# SLIMBUS2_L3Interconnect register map
Vendor: Texas Instruments
Registers are 32-bit, access per field, reset 0x0 unless marked. A register's access mark holds for its fields unless they carry their own. Offsets are as the file gives them; [hi:lo] are bit positions; {n}, {i} and the like mark numbered series; 'fields as' and 'values as' point back to an identical list; <NAME> marks a mode.

## SLIMBUS2_L3Interconnect (part 2 of 2)
0x78 SLIMBUS_FL_SM — Subframe mode (SM: defines control vs. data space partition) control and status Software must write in values : a) to use when booting in active framer mode. b) extracted from NEXT_SUBFRAME_MODE(SM), to use at following reconfiguration boundary. Hardware-updated upon superframe sync acquisition, when booting in clock receiver mode.
  [4:0] SM rw — Subframe Mode, which sets Control Space Width (CSW) and Subframe Length (SFL), both expressed in slots. Note that we always have CSW &lt;= SFL since the control is included in the subframe.
    13=CSW=3; SFL=8 (37.5% control); 21=CSW=6; SFL=8 (75% control); 30=reserved. Same effect than 0b00000; 8=CSW=2; SFL=6 (33.3% control); 5=CSW=1; SFL=8 (12.5% control); 27=CSW=12; SFL=32 (37.5% control); 2=reserved. Same as 0x00; 4=CSW=1; SFL=6 (16.7% control); 6=CSW=1; SFL=24 (4.17% control); 1=reserved. Same as 0x05; 29=CSW=16; SFL=32 (50% control); 0=CSW=8; SFL=8 (100% control vs. 0% data); 11=CSW=2; SFL=32 (6.25% control); 3=reserved. Same as 0x07; 23=CSW=6; SFL=32 (18.8% control); 17=CSW=4; SFL=8 (50% control); 10=CSW=2; SFL=24 (8.33% control); 9=CSW=2; SFL=8 (25% control); 16=CSW=4; SFL=6 (66.7% control); 18=CSW=4; SFL=24 (16.7% control); 19=CSW=4; SFL=32 (12.5% control); 24=CSW=8; SFL=24 (33.3% control); 20=reserved. Same as 0x00; 14=CSW=3; SFL=24 (12.5% control); 22=CSW=6; SFL=24 (25% control); 28=CSW=16; SFL=24 (66.7% control); 7=CSW=1; SFL=32 (3.13% control); 25=CSW=8; SFL=32 (25% control); 31=CSW=24; SFL=32 (75% control); 26=CSW=12; SFL=24 (50% control); 15=CSW=3; SFL=32 (9.38% control); 12=CSW=3; SFL=6 (50% control)
0x7C SLIMBUS_FL_CG — Clock Gear (CG) control and status Software must write in values : a) to use when booting in active framer mode. b) extracted from NEXT_CLOCK_GEAR(CG), to use at following reconfiguration boundary. Hardware-updated upon superframe sync acquisition, when booting in clock receiver mode.
  [3:0] CG rw — Clock Gear (CG) to be used after the next reconfiguration boundary. Root / SLIMbus frequency ratio is defined as 2
    6=Ratio to root frequency: 16; 1=Ratio to root frequency: 512; 10=Ratio to root frequency: 1 (undivided); 7=Ratio to root frequency: 8; 3=Ratio to root frequency: 128; 2=Ratio to root frequency: 256; 8=Ratio to root frequency: 4; 9=Ratio to root frequency: 2; 5=Ratio to root frequency: 32; 4=Ratio to root frequency: 64
0x80 SLIMBUS_FL_RF — Root frequency (RF = SLIMbus clock frequency when in gear 10) control and status Software must write in values : a) to use when booting in active framer mode. b) extracted from NEXT_ROOT_FREQUENCY(RF), to use at following reconfiguration boundary. Hardware-updated upon superframe sync acquisition, when booting in clock receiver mode.
  [3:0] RF rw — Root frequency
    {v}={v+18} MHz (v=6..9); 1=24.576 MHz; 0=Root frequency not indicated; 2=22.5792 MHz; 4=16.8 MHz; 5=19.2 MHz; 3=15.36 MHz
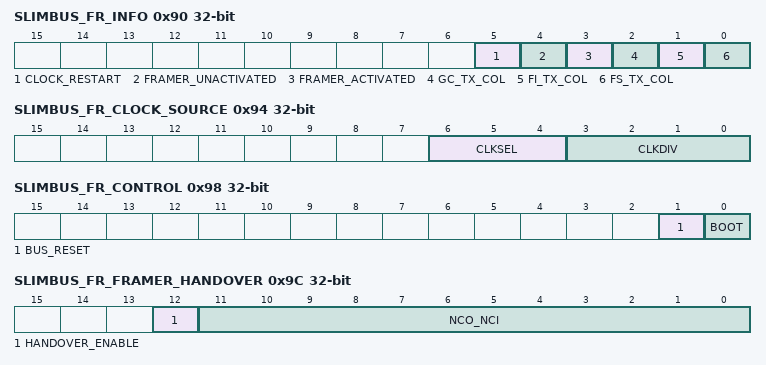
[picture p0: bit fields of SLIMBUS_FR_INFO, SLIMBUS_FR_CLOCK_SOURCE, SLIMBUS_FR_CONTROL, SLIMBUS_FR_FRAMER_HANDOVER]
0x90 SLIMBUS_FR_INFO access not given — Framer device status (when active). Write 1 to a bit to clear it.
  [all] fields
    0=no event pending; 1=event pending
  [5] CLOCK_RESTART — Clock restart request event detected (that is, asynchronous DATA line transition during clock pause) (access RW W1toClr)
  [4] FRAMER_UNACTIVATED — Framer has left clock source operational state. Set on ACTIVE_FRAMER information element deassertion. (framer device class-specific IE) (access RW W1toClr)
  [3] FRAMER_ACTIVATED — Framer has reached clock source operational state. Set on ACTIVE_FRAMER information element assertion. (framer device class-specific IE) (access RW W1toClr)
  [2] GC_TX_COL — Collision during guide byte transmit (Guide Channel) Framer device class-specific information element (IE) (access RW W1toClr)
  [1] FI_TX_COL — Collision during Framing Information transmit (framing channel) Framer device class-specific information element (IE) (access RW W1toClr)
  [0] FS_TX_COL — Collision during Frame Sync symbol transmit (framing channel) Framer device class-specific information element (IE) (access RW W1toClr)
0x94 SLIMBUS_FR_CLOCK_SOURCE — Root clock configuration for active framer mode, used at next reconfiguration boundary. Unused when not active framer.
  [6:4] CLKSEL rw — SLIMbus clock selection
    0=FCLK1; 1=FCLK2; 2=FCLK3
  [3:0] CLKDIV rw — Root divider ratio, applied on clock input to obtain root clock, to be used at next reconfiguration boundary. Input/ root frequency ratio is defined as 2 With CG the SLIMbus clock gear, Input / SLIMbus frequency ratio is therefore 2 WARNING: that last ratio has to be 1 or greater, to be implementable by the actual clock divider.
    6=Ratio is 2; 1=Ratio is 1/16: Gears 7 to 10 forbidden; 10=Ratio is 32; 7=Ratio is 4; 0=Ratio is 1/32: Gears 6 to 10 forbidden; 2=Ratio is 1/8: Gears 8 to 10 forbidden; 8=Ratio is 8; 9=Ratio is 16; 4=Ratio is 1/2: Gear 10 forbidden; 5=Ratio is 1 (root freq. = input freq.); 3=Ratio is 1/4: Gears 9-10 forbidden
0x98 SLIMBUS_FR_CONTROL — Framer Device control. Unused when not active framer. (Self-cleared bits)
  [1] BUS_RESET rw — Bus reset request control, when framer is already active. Set upon reception of the NEXT_RESET_BUS() message. Transitions clock source FSM to state 'StartingClock' (from 'Operational').
    0=BUS_RESET_0_w (Cancel pending request (not used in normal operation) if any, otherwise no action); 1=BUS_RESET_1_w (Assert request for next reconfiguration); 1=BUS_RESET_1_r (Request pending for next reconfiguration); 0=BUS_RESET_0_r (No request pending for next reconfiguration)
  [0] BOOT rw — Initiate an active framer (clock source) boot sequence for the component, that is, when component is default active framer. Transitions clock source FSM from state 'Undefined' to 'CheckingDataLine'. Transitions clock receiver FSM from state 'Undefined' to 'Reset'. No effect if bus has already booted.
    0=BOOT_0_w (Cancel pending request (not used in normal operation) if any, otherwise no action); 1=BOOT_1_w (Assert request for next reconfiguration); 1=BOOT_1_r (Request pending for next reconfiguration); 0=BOOT_0_r (No request pending for next reconfiguration)
0x9C SLIMBUS_FR_FRAMER_HANDOVER — Framer handover control (outgoing if currently active, incoming if currently inactive)
  [12] HANDOVER_ENABLE rw — Enable framer handover, upon NEXT_ACTIVE_FRAMER(NCi,NCo) reception. Self-cleared upon handover, that is, at next reconfiguration boundary.
    0=No framer handover; 1=Framer handover at next configuration boundary
  [11:0] NCO_NCI rw — NCo[11:0] / NCi[11:0] for outgoing / incoming framer respectively, as extracted from NEXT_ACTIVE_FRAMER(NCi,NCo) Used on framer handover at next reconfiguration boundary.
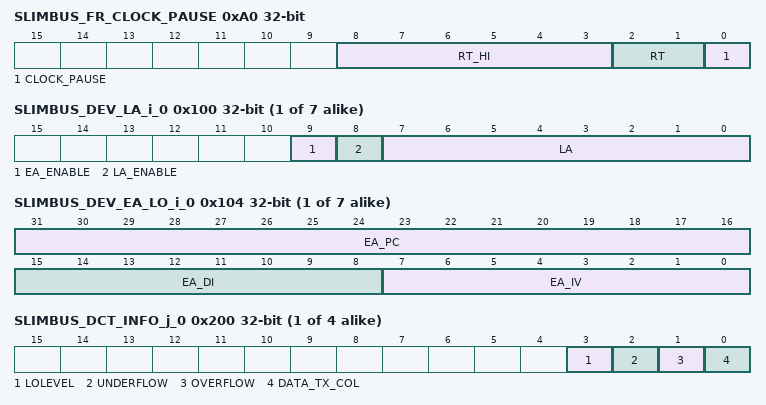
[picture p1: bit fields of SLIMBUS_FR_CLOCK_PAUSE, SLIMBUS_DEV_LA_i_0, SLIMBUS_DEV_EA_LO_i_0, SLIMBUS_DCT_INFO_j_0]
0xA0 SLIMBUS_FR_CLOCK_PAUSE — Clock and pause restart control. Applied at following reconfiguration boundary, that is, where the clock is paused. Note that programming is indentical for an active framer (clock source) and a clock receiver.
  [8:3] RT_HI ro — MSBs of 8-bit SLIMbus parameter. Constant.
    0=RT_HI_0_r (Only legal, unreserved value.)
  [2:1] RT rw — Restart Time (RT) for recovery after clock pause, as extracted from NEXT_PAUSE_CLOCK(RT) LSBs of 8-bit SLIMbus parameter. Unused when not active framer.
    0=Fast recovery (less than 4 cells); 1=Constant-phase recovery (superframe phase preserved); 2=Unspecified recovery delay
  [0] CLOCK_PAUSE rw — Control clock pause / restart. Self-cleared upon restart.
    0=Force clock restart if paused, no effect otherwise; 1=Pause clock (clock source) or expect clock pause (clock receiver) at next configuration boundary
{0x100+0x10*i} SLIMBUS_DEV_LA_i_{i} (i=0..6) — Device Logical Address control
  [9] EA_ENABLE rw — Enables the reception of 'long-header' messages to the device's hardwired Enumeration Address (EA). Don't care if LA_ENABLE is 1.
    0=EA is not valid; 1=EA is used for message reception
  [8] LA_ENABLE rw — Enables the reception of 'short-header' messages to the device's Logical Address (LA).
    0=LA is not valid; 1=LA valid, to be used for message reception
  [7:0] LA rw — Device Logical Address, assigned by manager device at enumeration (0x00 through 0xEF). The active manager device itself has address 0xFF by default.
    255=active manager device address
{0x104+0x10*i} SLIMBUS_DEV_EA_LO_i_{i} ro (i=0..6) — Device's Enumeration Address (EA[47:0]), lower 32 bits. For reference.
  [31:16] EA_PC — Product Code (PC[15:0]), shared by all devices of the component
  [15:8] EA_DI — Device Index (DI[15:0]), hardcoded from 0 upwards (0x00,0x01,0x02, etc...) each device of the component. WARNING: value is incorrectly given as 0x00 for all indexes.
  [7:0] EA_IV — Component's Instance Value (IV[7:0]), shared by all devices of the component
{0x108+0x10*i} SLIMBUS_DEV_EA_HI_i_{i} ro reset 0x102 (i=0..6) — Device's Enumeration Address (EA[47:0]), upper 16 bits. For reference.
  [15:0] EA_MI — Manufacturer Index (MI[15:0]), shared by all devices
{0x200+0x20*i} SLIMBUS_DCT_INFO_j_{i} access not given (i=0..3) — TX data agent status. Write 1 to a bit to clear it.
  [3] LOLEVEL — Write level of TX data agent FIFO has gone above DMA threshold (that is, writes required to fill FIFO) Note: Defaults to 0 (even though FIFO is then empty) as it sets to 1 only when read-only status bit DCT_FIFO_STATUS.LOLEVEL transitions from 0 to 1, that is, when threshold is actually crossed downward. (access RW W1toClr)
    0=LOLEVEL_0_w (No action); 1=LOLEVEL_1_w (Clear pending event, if any); 1=LOLEVEL_1_r (IRQ event pending); 0=LOLEVEL_0_r (No event pending)
  [2] UNDERFLOW — Underflow in TX data agent FIFO. Note: never asserted in pushed or async TPs, by construction. (access RW W1toClr)
    0=UNDERFLOW_0_w (No action); 1=UNDERFLOW_1_w (Clear pending event, if any); 1=UNDERFLOW_1_r (IRQ event pending); 0=UNDERFLOW_0_r (No event pending)
  [1] OVERFLOW — Overflow in TX data agent FIFO. (access RW W1toClr)
    0=OVERFLOW_0_w (No action); 1=OVERFLOW_1_w (Clear pending event, if any); 1=OVERFLOW_1_r (IRQ event pending); 0=OVERFLOW_0_r (No event pending)
  [0] DATA_TX_COL — TX collision in TX data agent. Core information element (IE). (access RW W1toClr)
    0=DATA_TX_COL_0_w (No action); 1=DATA_TX_COL_1_w (Clear pending event, if any); 1=DATA_TX_COL_1_r (IRQ event pending); 0=DATA_TX_COL_0_r (No event pending)
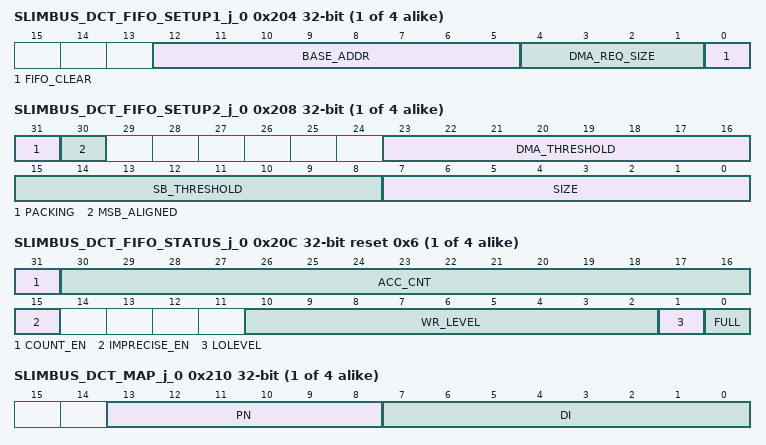
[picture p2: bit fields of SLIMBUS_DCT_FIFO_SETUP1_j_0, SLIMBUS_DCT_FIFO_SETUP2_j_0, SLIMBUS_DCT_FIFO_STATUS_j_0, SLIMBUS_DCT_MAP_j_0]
{0x204+0x20*i} SLIMBUS_DCT_FIFO_SETUP1_j_{i} (i=0..3) — TX data agent FIFO setup. To be kept static during channel operation.
  [12:5] BASE_ADDR rw — TX data agent FIFO base address within shared TX RAM. (physical address of the 32-bit wide RAM array)
  [4:1] DMA_REQ_SIZE rw — DMA request size minus 1, in write accesses. In counting (packet) mode, last request may be smaller. Only applicable in precise DMA mode.
    15=16 accesses per DMA request; 0=1 access per DMA request
  [0] FIFO_CLEAR rw — Returns FIFO to initial empty state.
    0=FIFO_CLEAR_0_w (No effect); 1=FIFO_CLEAR_1_w (Clear FIFO); 1=FIFO_CLEAR_1_r (Ongoing Clear. Completion requires the SLIMbus clock.); 0=FIFO_CLEAR_0_r (No event, last clear completed)
{0x208+0x20*i} SLIMBUS_DCT_FIFO_SETUP2_j_{i} (i=0..3) — TX data agent FIFO setup, continued. To be kept static during channel operation.
  [31] PACKING rw — Packing enable control
    0=Packing disabled: one segment word per write access. Byte enable is don't care.; 1=Packing enabled: one or several segment words per write access, depending on segment word size and byte enable. Only works in LSB-aligned mode. Behaviour in LSB-aligned mode is undefined.
  [30] MSB_ALIGNED rw — PLACEHOLDER, NO EFFECT: DATA ALWAYS LSB-aligned LSB/MSB-alignment of FIFO input (write) TX data.
    0=Input data is LSB-aligned; 1=Input data is MSB-aligned
  [23:16] DMA_THRESHOLD rw — SW-side TX data agent FIFO threshold. DMA write requests get (re-)asserted when WR_LEVEL is above threshold. Range: 0 to SIZE field value (included).
    255=DMA writes requested whenever FIFO is empty (assuming maximum FIFO size); 0=DMA writes requested whenever FIFO is not full
  [15:8] SB_THRESHOLD rw — SLIMbus-side TX data agent FIFO threshold, used for SLIMbus transmission.
    255=Threshold condition = FIFO is full (assuming maximum FIFO size); 0=Threshold condition = FIFO is not empty
  [7:0] SIZE rw — Capacity of FIFO in segment words, minus one.
    255=Maximum FIFO size; 0=FIFO is 1-word deep (not recommended); 3=FIFO is 4-word deep. Recommended minimum setting (SLIMbus protocol).
{0x20C+0x20*i} SLIMBUS_DCT_FIFO_STATUS_j_{i} reset 0x6 (i=0..3) — TX data agent FIFO status, for software (non-DMA) FIFO management.
  [31] COUNT_EN rw — Down-counter mode control. Only applicable in precise DMA mode.
    0=COUNT_EN_0_w (Disable down-counter mode. Should typically be used only when ACC_CNT = 0. If ACC_CNT > 0, DMA request gets deasserted immediately.); 1=COUNT_EN_1_w (Enable down-counter mode. ACC_CNT is typically set to the desired value in the same write access.); 1=COUNT_EN_1_r (Down-counter mode is enabled. DMA request can only be active when ACC_CNT > 0); 0=COUNT_EN_0_r (Down-counter mode is disabled: DMA request follows FIFO level, and is active during no-tx periods.)
  [30:16] ACC_CNT rw — 'Packet mode' down-counter of segment words, decremented on DCT_DATA write accesses. In that mode, DMA request shall deassert when ACC_CNT = 0 (that is, packet fully transmitted / stored in TX FIFO).
    0=ACC_CNT_0_w (Deasserts current DMA request by forcing the count to zero (not typical operation)); 127=ACC_CNT_127_w (Set largest packet size (in accesses) to transfer before DMA request deassertion. Any lower value is also valid to enter.); 127=ACC_CNT_127_r (Maximum number of accesses still to be transferred before DMA deassertion. Unless interrupted, counter shall go through all values down to zero.); 0=ACC_CNT_0_r (No access left to transfer, DMA request currently inactive.)
  [15] IMPRECISE_EN rw — Precise vs. Imprecise DMA requesting mode control. (A DMA request is a single assertion-deassertion cycle.)
    0=DMA request contains a precise number of accesses; 1=DMA request is not expected to trigger a fixed number of accesses
  [10:2] WR_LEVEL ro — Number of free segment words in FIFO, that could be filled by writes.
    0x100=WR_LEVEL_256_r (FIFO is empty and entirely available for writes (assuming maximum FIFO size)); 0=WR_LEVEL_0_r (FIFO is full and cannot be written to)
  [1] LOLEVEL ro — Indicator of write level (WR_LEVEL: number of free words in FIFO) with respect to (write) threshold (DMA_threshold). Activates DMA write requests when high.
    1=LOLEVEL_1_r (WR_LEVEL > DMA_THRESHOLD); 0=LOLEVEL_0_r (WR_LEVEL <= DMA_THRESHOLD)
  [0] FULL ro — FIFO full indicator
    1=FULL_1_r (no space left in FIFO to write a word (WR_LEVEL = 0)); 0=FULL_0_r (some space left in FIFO to write at least one word (WR_LEVEL > 0))
{0x210+0x20*i} SLIMBUS_DCT_MAP_j_{i} (i=0..3) — Associates a device and port to the TX data agent. Write to field FL_CONTROL.validate_dcmap to validate changes.
  [13:8] PN rw — Port Number (PN), identifies the data channel's port for the device. Shall be unique within a device. Note that a half-duplex (bidirectional) port has 2 data agents with the same PN, 1 TX + 1 Rx.
  [7:0] DI rw — Index (DI) of the device this data agent belongs to. Devices are hard-indexed from 0 upwards.
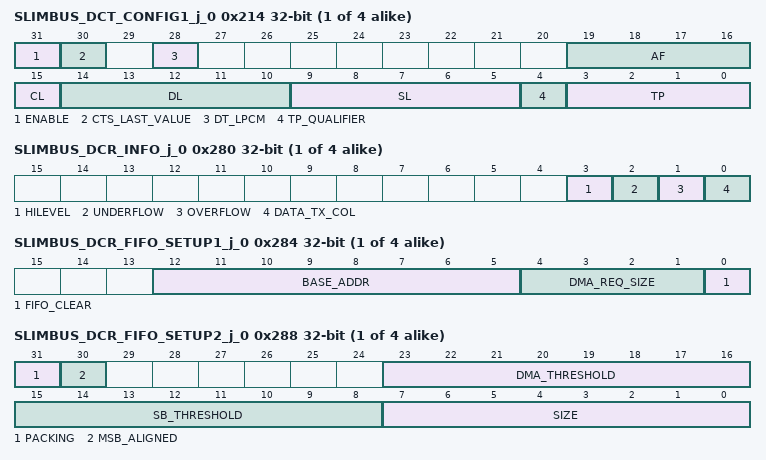
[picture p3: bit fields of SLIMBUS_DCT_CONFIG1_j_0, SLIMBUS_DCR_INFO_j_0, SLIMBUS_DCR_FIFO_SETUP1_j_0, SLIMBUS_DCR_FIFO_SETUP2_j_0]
{0x214+0x20*i} SLIMBUS_DCT_CONFIG1_j_{i} (i=0..3) — TX data agent configuration, applied at the next reconfiguration boundary
  [31] ENABLE rw — Data agent enabling control. Auto-cleared upon frame or superframe sync loss.
    1=ENABLE_1_r (Data agent is enabled); 0=ENABLE_0_r (Data agent is disabled)
  [30] CTS_LAST_VALUE ro — Last received value of the CTS TAG bit. Only updated for asynchronous TP, when primary owner (that is, transmitter) of the channel.
    1=CTS_LAST_VALUE_1_r (Local sink signals TAG.CTS=1 that is, it can receive data (and remote source can transmit some)); 0=CTS_LAST_VALUE_0_r (Local sink signals TAG.CTS=0 that is, it cannot receive any data (and remote source shall not transmit any))
  [28] DT_LPCM rw — Unsigned-to-OSAM encoding enable for Data Type (DT) = LPCM audio (0x1)
    0=DT!=0x1: encoding disabled; 1=DT=0x1: encoding enabled
  [19:16] AF rw — Auxillairy Format (AF) used in segment word size calculation. Non-zero values not supported in extended asynchronous TPs.
    15=User-defined 8-bit AUX (2 AUX slot per segment); 0=No AUX information (0 AUX slots per segment); 1=ZCUV for tunneling IEC60958 (1 AUX slot per segment); 11=User-defined 4-bit AUX (1 AUX slot per segment)
  [15] CL rw — Channel Link (CL) enable: Pairing up of current channel with previous one (that is, channel index below) Tied-0, read-only field for channel index 0, since there is no 'previous' channel in that case. TP and segment interval (encoded in SD) must be equal between the linked channels.
    0=Current channel independent from previous one; 1=Current channel paired up with previous one
  [14:10] DL rw — Segment Data Length (DL), in 4-bit slots (except when 0). AUX + DATA length shall fit in a segment word, that is, 1 to 32 bits. In extended async TPs, sets segment word size (0 and odd values illegal) instead.
    6=6 slots (24 bits); 1=1 slot (4 bits); 7=7 slots (28 bits), requiring at most 1 AUX slot to fit in max-size 32-bit segment word; 0=Length not indicated: Segment slots that are not TAG or AUX are DATA (that is, no unused slot); 2=2 slots (8 bits); 8=8 slots (32 bits), requiring zero AUX slot, to fit in a max-size 32-bit segment word; 4=4 slots (16 bits); 5=5 slots (20 bits); 3=3 slots (12 bits)
  [9:5] SL rw — total Segment Length (SL), in 4-bit slots. SL &gt;= TAG length + AUX length + DATA length
    0=Reseved value
  [4] TP_QUALIFIER rw — Qualifier for plain/extended half-duplex asynchronous TPs (owner ID). Unused and don't care for other TPs.
    0=1/2 duplex TPs: Local device is primary channel owner, uses T1 token; 1=1/2 duplex TPs: Local device is secondary channel owner, uses T2 token
  [3:0] TP rw — Transport Protocol (TP) Determines also the TAG length (from 0 to 2 slots).
    6=Extended asynchronous-half-duplex (unicast, 2-slot TAG); 1=Pushed (multicast, 1-slot TAG); 7=Extended asynchronous-simplex (unicast, 2-slot TAG); 0=Isochronous (multicast, no TAG); 2=Pulled (unicast, 1-slot TAG); 4=Asynchronous-simplex (unicast, 1-slot TAG); 5=Asynchronous-half-duplex (unicast, 1-slot TAG); 15=User-defined protocol 2 NOT SUPPORTED, RESERVED VALUE; 3=Locked (multicast, no TAG) NOT SUPPORTED, RESERVED VALUE; 14=User-defined protocol 1 NOT SUPPORTED, RESERVED VALUE
{0x218+0x20*i} SLIMBUS_DCT_CONFIG2_j_{i} (i=0..3) — TX data agent configuration (continued), applied at the next reconfiguration boundary
  [11:0] SD rw — Segment Distribution (see)
{0x21C+0x20*i} SLIMBUS_DCT_DATA_j_{i} rw (i=0..3) — TX data agent DATA FIFO input. Reads have no effect on FIFO.
  [31:0] DATA — Data segment word, single-word or packed, LSB or MSB-aligned.
{0x280+0x20*i} SLIMBUS_DCR_INFO_j_{i} access not given (i=0..3) — RX data agent status. Write 1 to a bit to clear it.
  [3] HILEVEL — Read level of RX data agent FIFO has gone above DMA threshold (that is, reads required to empty FIFO) (access RW W1toClr)
    0=HILEVEL_0_w (No action); 1=HILEVEL_1_w (Clear pending event, if any); 1=HILEVEL_1_r (IRQ event pending); 0=HILEVEL_0_r (No event pending)
  [2] UNDERFLOW — Underflow in RX data agent FIFO (access RW W1toClr)
    values as SLIMBUS_DCT_INFO_j_0.UNDERFLOW
  [1] OVERFLOW — Overflow in RX data agent FIFO Note: never asserted in pulled or async TPs, by construction. (access RW W1toClr)
    values as SLIMBUS_DCT_INFO_j_0.OVERFLOW
  [0] DATA_TX_COL — TX collision in RX data agent. Core information element (IE). (access RW W1toClr)
    values as SLIMBUS_DCT_INFO_j_0.DATA_TX_COL
{0x284+0x20*i} SLIMBUS_DCR_FIFO_SETUP1_j_{i} (i=0..3) — RX data agent FIFO setup. To be kept static during channel operation.
  [12:5] BASE_ADDR rw — RX data agent FIFO base address within shared RX RAM. (physical address of the 32-bit wide RAM array)
  [4:1] DMA_REQ_SIZE rw — DMA request size minus 1, in read accesses. In counting (packet) mode, last request may be smaller. Only applicable in precise DMA mode.
    15=16 accesses per DMA request; 0=1 access per DMA request
  [0] FIFO_CLEAR rw — Returns FIFO to initial empty state.
    values as SLIMBUS_DCT_FIFO_SETUP1_j_0.FIFO_CLEAR
{0x288+0x20*i} SLIMBUS_DCR_FIFO_SETUP2_j_{i} (i=0..3) — RX data agent FIFO setup, continued. To be kept static during channel operation.
  [31] PACKING rw — Packing enable control
    0=Packing disabled: one segment word per read access. Byte enable is don't care.; 1=Packing enabled: one or several segment words per read access, depending on segment word size and byte enable. Only works in LSB-aligned mode. Behaviour in LSB-aligned mode is undefined.
  [30] MSB_ALIGNED rw — PLACEHOLDER, NO EFFECT: DATA ALWAYS LSB-aligned LSB/MSB-alignment of FIFO output (read) RX data.
    0=Output data is LSB-aligned; 1=Output data is MSB-aligned
  [23:16] DMA_THRESHOLD rw — SW-side RX data agent FIFO threshold. DMA read requests get (re-)asserted when RD_LEVEL is above threshold. Range: 0 to SIZE field value (included).
    255=DMA reads requested whenever FIFO is full (assuming maximum FIFO size); 0=DMA reads requested whenever FIFO is not empty
  [15:8] SB_THRESHOLD rw — SLIMbus-side RX data agent FIFO threshold, used for SLIMbus reception.
    values as SLIMBUS_DCT_FIFO_SETUP2_j_0.SB_THRESHOLD
  [7:0] SIZE rw — Capacity of FIFO in segment words, minus one.
    values as SLIMBUS_DCT_FIFO_SETUP2_j_0.SIZE
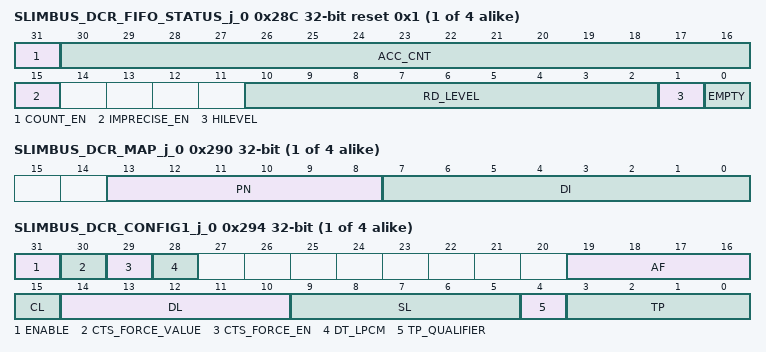
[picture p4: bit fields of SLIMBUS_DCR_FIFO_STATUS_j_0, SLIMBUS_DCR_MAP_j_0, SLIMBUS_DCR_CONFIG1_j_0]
{0x28C+0x20*i} SLIMBUS_DCR_FIFO_STATUS_j_{i} reset 0x1 (i=0..3) — RX data agent FIFO status, for software (non-DMA) FIFO management.
  [31] COUNT_EN rw — Down-counter mode control. Only applicable in precise DMA mode.
    0=COUNT_EN_0_w (Disable down-counter mode. Should typically be used only when ACC_CNT = 0. If ACC_CNT > 0, DMA request gets deasserted immediately.); 1=COUNT_EN_1_w (Enable down-counter mode. ACC_CNT is typically set to the desired value in the same write access.); 1=COUNT_EN_1_r (Down-counter mode is enabled: DMA request can only be active when ACC_CNT > 0); 0=COUNT_EN_0_r (Down-counter mode is disabled: DMA request follows FIFO level, and is active during no-transmission periods.)
  [30:16] ACC_CNT rw — 'Packet mode' down-counter of segment words, decremented on DCR_DATA read accesses. In that mode, DMA request shall reassert when ACC_CNT = RD_LEVEL (that is, whole packet received).
    values as SLIMBUS_DCT_FIFO_STATUS_j_0.ACC_CNT
  [15] IMPRECISE_EN rw — Precise vs. Imprecise DMA requesting mode control. (A DMA request is a single assertion-deassertion cycle.)
    0=DMA request contains a defined number of accesses; 1=DMA request is not expected to trigger a fixed number of accesses
  [10:2] RD_LEVEL ro — Number of segment words stored in FIFO, that can be read out.
    0x100=RD_LEVEL_256_r (FIFO is full of readable words (assuming maximum size)); 0=RD_LEVEL_0_r (FIFO contains no readable word)
  [1] HILEVEL ro — Indicator of read level (RD_LEVEL: number of readable segment words) with respect to (read) threshold (DMA_THRESHOLD). Activates DMA read requests when high.
    1=HILEVEL_1_r (RD_LEVEL > DMA_THRESHOLD); 0=HILEVEL_0_r (RD_LEVEL <= DMA_THRESHOLD)
  [0] EMPTY ro — FIFO empty indicator
    1=EMPTY_1_r (FIFO contains no readable word (RD_LEVEL = 0)); 0=EMPTY_0_r (FIFO contains at least one readable word (RD_LEVEL > 0))
{0x290+0x20*i} SLIMBUS_DCR_MAP_j_{i} (i=0..3) — Associates a device and port to the RX data agent. Write to field FL_CONTROL[8] VALIDATE_DCMAP to validate changes.
  fields as SLIMBUS_DCT_MAP_j_0
{0x294+0x20*i} SLIMBUS_DCR_CONFIG1_j_{i} (i=0..3) — RX data agent configuration, applied at the next reconfiguration boundary
  [31] ENABLE rw — Data agent enabling control. Auto-cleared upon frame or superframe sync loss.
    0=Data agent is disabled; 1=Data agent is enabled
  [30] CTS_FORCE_VALUE rw — Value to force the CTS TAG bit value when in asynchronous TP and secondary channel owner (that is, receiver) and CTS is forced (CTS_force_en=1) Don't care in all other cases. Warning: forcing CTS=1 can result in a FIFO overflow.
    0=Local sink signals TAG.CTS=0 that is, it cannot receive any data (and remote source shall not transmit any); 1=Local sink signals TAG.CTS=1 that is, it can receive data (and remote source can transmit some)
  [29] CTS_FORCE_EN rw — Forces the CTS TAG bit value when in an asynchronous TP and secondary owner (that is, receiver) of the channel. Don't care in other cases.
    0=CTS bit generated according to RX FIFO level; 1=CTS bit forced to CTS_force_value
  [28] DT_LPCM rw — OSAM-to-unsigned decoding enable for Data Type (DT) = LPCM audio (0x1)
    0=DT!=0x1: decoding disabled; 1=DT=0x1: decoding enabled
  [19:16] AF rw — Auxillairy Format (AF) used in segment word size calculation. Non-zero values not supported in extended asynchronous TPs.
    values as SLIMBUS_DCT_CONFIG1_j_0.AF
  [15] CL rw — Channel Link (CL) enable: Pairing up of current channel with previous one (that is, channel index below) Channel index 0 should have CL=0, since there is no 'previous' channel in that case. TP and segment interval (encoded in SD) must be equal between the linked channels.
    values as SLIMBUS_DCT_CONFIG1_j_0.CL
  [14:10] DL rw — Segment Data Length (DL), in 4-bit slots (except when 0). AUX + DATA length shall fit in a segment word, that is, 1 to 32 bits. In extended async TPs, sets segment word size (0 and odd values illegal) instead.
    values as SLIMBUS_DCT_CONFIG1_j_0.DL
  [9:5] SL rw — total Segment Length (SL), in 4-bit slots. SL &gt;= TAG length + AUX length + DATA length
    0=Reseved value
  [4] TP_QUALIFIER rw — Qualifier for plain/extended half-duplex asynchronous TPs (owner ID). Unused and don't care for other TPs
    values as SLIMBUS_DCT_CONFIG1_j_0.TP_QUALIFIER
  [3:0] TP rw — Transport Protocol (TP) Determines also the TAG length (from 0 to 2 slots).
    values as SLIMBUS_DCT_CONFIG1_j_0.TP
{0x298+0x20*i} SLIMBUS_DCR_CONFIG2_j_{i} (i=0..3) — RX data agent configuration (continued), applied at the next reconfiguration boundary
  [11:0] SD rw — Segment Distribution
{0x29C+0x20*i} SLIMBUS_DCR_DATA_j_{i} ro (i=0..3) — RX data agent DATA FIFO output. Writes have no effect on FIFO.
  fields as SLIMBUS_DCT_DATA_j_0
